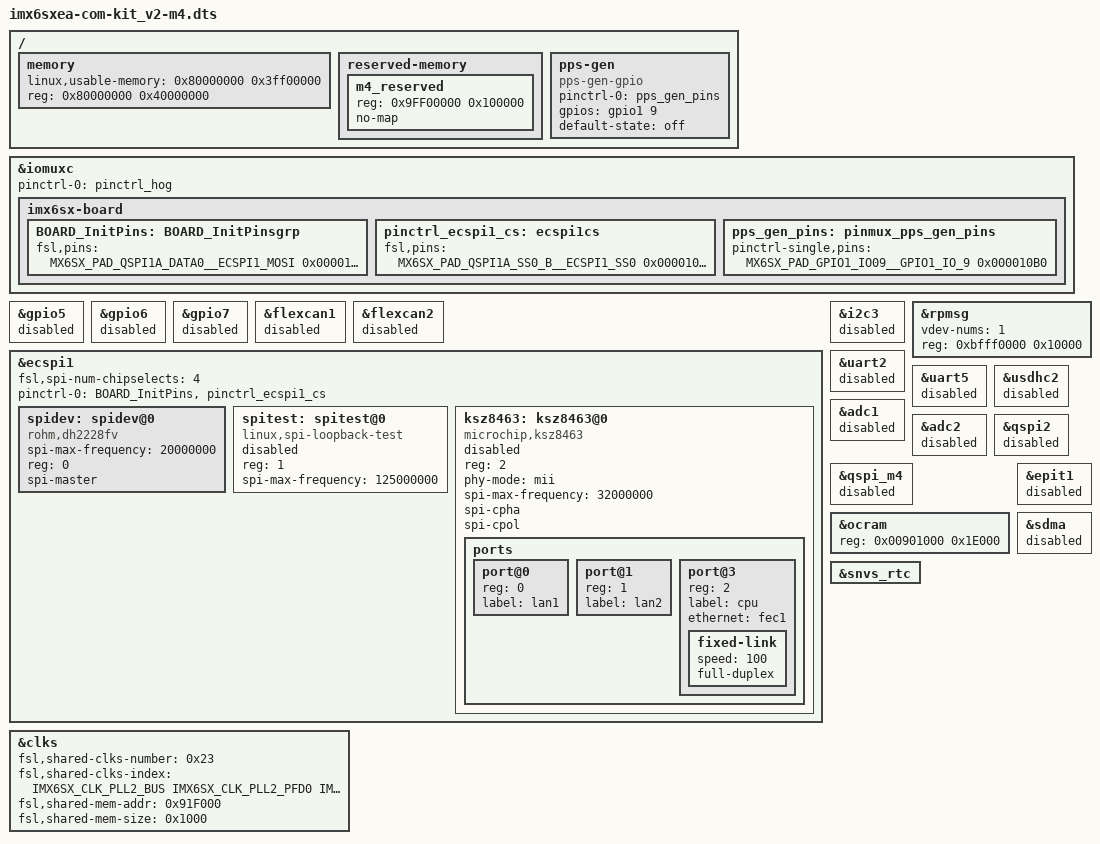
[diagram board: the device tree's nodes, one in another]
/*
 * Copyright (C) 2014-2015 Freescale Semiconductor, Inc.
 *
 * This program is free software; you can redistribute it and/or modify
 * it under the terms of the GNU General Public License version 2 as
 * published by the Free Software Foundation.
 */

#include "imx6sxea-com-kit_v2.dts"


#define CONFIG_CONT1_SPI_A

/{
	memory {
		linux,usable-memory = <0x80000000 0x3ff00000>;
		reg = <0x80000000 0x40000000>;
	};
reserved-memory {
                m4_reserved{
                        reg = <0x9FF00000 0x100000>;
                        no-map;
                };
		/*linux,cma {
			size = <0x2000000>;
		};*/
};/*vf*/

pps-gen {
	pinctrl-names = "default";
	pinctrl-0 = <&pps_gen_pins>;
	compatible = "pps-gen-gpio";
	gpios = <&gpio1 9>;
	default-state = "off";
};

// pps {
// 		pinctrl-names = "default";
// 		pinctrl-0 = <&pinctrl_pps>;

// 		gpios = <&gpio1 26 GPIO_ACTIVE_HIGH>;
// 		assert-falling-edge;

// 		echo-gpios = <&gpio1 27 GPIO_ACTIVE_HIGH>;
// 		echo-active-ms = <100>;

// 		compatible = "pps-gpio";
// 	};

/*pps {
	pinctrl-names = "default";
	pinctrl-0 = <&pinctrl_pps>;

	gpios = <&gpio1 9 GPIO_ACTIVE_HIGH>;
	assert-falling-edge;

	compatible = "pps-gpio";
	status = "okay";
};*/
};


//st

&iomuxc {
    pinctrl-names = "default";
    pinctrl-0 = <&pinctrl_hog>;

    imx6sx-board {
		
			BOARD_InitPins: BOARD_InitPinsgrp {     
				fsl,pins = <
					MX6SX_PAD_QSPI1A_DATA0__ECSPI1_MOSI        0x000010B0
					MX6SX_PAD_QSPI1A_DATA1__ECSPI1_MISO        0x000010B0
					MX6SX_PAD_QSPI1A_SCLK__ECSPI1_SCLK         0x000010B0
					
				>;
			};
			pinctrl_ecspi1_cs: ecspi1cs {                        
				fsl,pins = <                                
				MX6SX_PAD_QSPI1A_SS0_B__ECSPI1_SS0         0x000010B0                        
				>;                
				};
			pps_gen_pins: pinmux_pps_gen_pins {
  			pinctrl-single,pins = <
				MX6SX_PAD_GPIO1_IO09__GPIO1_IO_9           0x000010B0
				
			>;
			};

		
	};
};

/*
 * The following modules are conflicting with M4, disable them when m4
 * is running.
 */

&gpio5 {
	status = "disabled";
};

&gpio6 {
	status = "disabled";
};

&gpio7 {
	status = "disabled";
};

&flexcan1 {
	status = "disabled";
};

&flexcan2 {
	status = "disabled";
};

&ecspi1 {

	fsl,spi-num-chipselects = <4>;        
	//cs-gpios = <&gpio4 19 0>;
   pinctrl-names = "default";
   pinctrl-0 = <&BOARD_InitPins &pinctrl_ecspi1_cs>;
   status = "okay";

   	spidev: spidev@0 {
			compatible = "rohm,dh2228fv";
			spi-max-frequency = <20000000>;
			reg = <0>;
			spi-master;
			status = "okay";
	};

	spitest: spitest@0{
		compatible = "linux,spi-loopback-test";
		reg = <1>;
		spi-max-frequency = <125000000>;
		status = "disabled";
	};
	ksz8463: ksz8463@0 {
		compatible = "microchip,ksz8463";
		reg = <2>;
		phy-mode = "mii";
		spi-max-frequency = <32000000>;
		spi-cpha;
		spi-cpol;
		status = "disabled";

		ports {
			#address-cells = <1>;
			#size-cells = <0>;

			port@0 {
					reg = <0>;
					label = "lan1";
			};

			port@1 {
					reg = <1>;
					label = "lan2";
			};

			port@3 {
				reg = <2>;
				label = "cpu";
				ethernet = <&fec1>;
				fixed-link {
					speed = <100>;
					full-duplex;
				};
			};
		};
	};



};	


&i2c3 {
        status = "disabled";
};

&rpmsg {
	vdev-nums = <1>;
	reg = <0xbfff0000 0x10000>;
	status = "okay";
};

&uart2 {
	status = "disabled";
};

&uart5 {
	status = "disabled";
};//vf

&usdhc2 {
        status = "disabled";
};//vf

&adc1 {
        status = "disabled";
};

&adc2 {
        status = "disabled";
};

&qspi2 {
	status = "disabled";
};

&qspi_m4 {
	status = "disabled";//vf
};
&ocram {
	reg = <0x00901000 0x1E000>;
};

&snvs_rtc {
   status = "okay";
};//vf

&epit1 {
	status = "disabled";//st
}
// &epit2 {
// 	status = "disabled";//st
// }
&sdma{
	status = "disabled";//st
}
&clks {
	fsl,shared-clks-number = <0x23>;
	fsl,shared-clks-index = <IMX6SX_CLK_PLL2_BUS IMX6SX_CLK_PLL2_PFD0
			IMX6SX_CLK_PLL2_PFD2 IMX6SX_CLK_PLL3_USB_OTG
			IMX6SX_CLK_PLL3_PFD1 IMX6SX_CLK_PLL3_PFD2
			IMX6SX_CLK_PLL3_PFD3 IMX6SX_CLK_PLL4_AUDIO
			IMX6SX_CLK_PLL5_VIDEO
			IMX6SX_CLK_OCRAM IMX6SX_CLK_CAN1_SERIAL
			IMX6SX_CLK_CAN1_IPG IMX6SX_CLK_CAN2_SERIAL
			IMX6SX_CLK_CAN2_IPG IMX6SX_CLK_CANFD
			IMX6SX_CLK_ECSPI1 IMX6SX_CLK_ECSPI2
			IMX6SX_CLK_ECSPI3 IMX6SX_CLK_ECSPI4
			IMX6SX_CLK_ECSPI5 IMX6SX_CLK_QSPI1
			IMX6SX_CLK_QSPI2 IMX6SX_CLK_SSI1
			IMX6SX_CLK_SSI2 IMX6SX_CLK_SSI3
			IMX6SX_CLK_UART_SERIAL IMX6SX_CLK_UART_IPG
			IMX6SX_CLK_PERIPH_CLK2_SEL IMX6SX_CLK_DUMMY
			IMX6SX_CLK_I2C1 IMX6SX_CLK_I2C2
			IMX6SX_CLK_I2C3 IMX6SX_CLK_I2C4
			IMX6SX_CLK_EPIT1 IMX6SX_CLK_EPIT2>;
	fsl,shared-mem-addr = <0x91F000>;
	fsl,shared-mem-size = <0x1000>;
};

